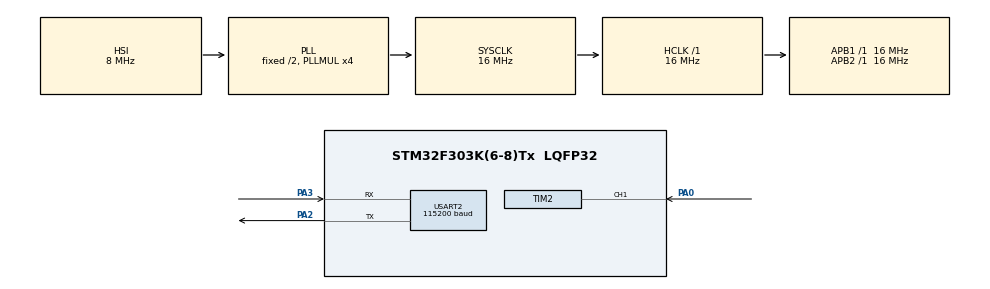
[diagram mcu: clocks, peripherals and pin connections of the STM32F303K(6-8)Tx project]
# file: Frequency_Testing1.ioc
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Mcu.Family=STM32F3
Mcu.Name=STM32F303K(6-8)Tx
Mcu.Package=LQFP32
NVIC.PriorityGroup=NVIC_PRIORITYGROUP_4
NVIC.TIM2_IRQn=true\:0\:0\:false\:false\:true\:true\:true\:true
NVIC.TIM7_DAC2_IRQn=true\:15\:0\:false\:false\:true\:false\:true\:true
NVIC.TimeBase=TIM7_DAC2_IRQn
NVIC.TimeBaseIP=TIM7
PA0.Signal=S_TIM2_CH1_ETR
PA13.Mode=Serial_Wire
PA13.Signal=SYS_JTMS-SWDIO
PA14.Mode=Serial_Wire
PA14.Signal=SYS_JTCK-SWCLK
PA2.Mode=Asynchronous
PA2.Signal=USART2_TX
PA3.Mode=Asynchronous
PA3.Signal=USART2_RX
PF0\ /\ OSC_IN.Mode=HSE-External-Clock-Source
PF0\ /\ OSC_IN.Signal=RCC_OSC_IN
ProjectManager.HeapSize=0x200
ProjectManager.StackSize=0x400
ProjectManager.TargetToolchain=STM32CubeIDE
RCC.AHBFreq_Value=16000000
RCC.APB1Freq_Value=16000000
RCC.APB1TimFreq_Value=16000000
RCC.APB2Freq_Value=16000000
RCC.APB2TimFreq_Value=16000000
RCC.CortexFreq_Value=16000000
RCC.HCLKFreq_Value=16000000
RCC.HSE_VALUE=8000000
RCC.HSI_VALUE=8000000
RCC.PLLMUL=RCC_PLL_MUL4
RCC.SYSCLKFreq_VALUE=16000000
RCC.SYSCLKSourceVirtual=RCC_SYSCLKSOURCE_PLLCLK
SH.S_TIM2_CH1_ETR.0=TIM2_CH1,Input_Capture1_from_TI1
TIM2.Channel-Input_Capture1_from_TI1=TIM_CHANNEL_1
TIM2.Prescaler=16-1
USART2.BaudRate=115200
USART2.VirtualMode-Asynchronous=VM_ASYNC
VP_SYS_VS_tim7.Mode=TIM7
VP_TIM2_VS_ClockSourceINT.Mode=Internal
board=custom

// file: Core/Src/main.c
/* USER CODE BEGIN Header */
/**
  ******************************************************************************
  * @file           : main.c
  * @brief          : Main program body
  ******************************************************************************
  * @attention
  *
  * Copyright (c) 2024 STMicroelectronics.
  * All rights reserved.
  *
  * This software is licensed under terms that can be found in the LICENSE file
  * in the root directory of this software component.
  * If no LICENSE file comes with this software, it is provided AS-IS.
  *
  ******************************************************************************
  */
/* USER CODE END Header */
#include "main.h"
#include "stdio.h"
#include "string.h"

TIM_HandleTypeDef htim2;

UART_HandleTypeDef huart2;

void SystemClock_Config(void);
static void MX_GPIO_Init(void);
static void MX_USART2_UART_Init(void);
static void MX_TIM2_Init(void);

/* USER CODE BEGIN 0 */
#define TIMCLOCK   16000000
#define PRESCALER  15

uint32_t IC_Val1 = 0;
uint32_t IC_Val2 = 0;
uint32_t Difference = 0;
int Is_First_Captured = 0;
float frequency = 0;

void Print_Frequency(void) {
    char buffer[50]; // Buffer to hold the string
    int len = sprintf(buffer, "Frequency: %.2f Hz\r\n", frequency); // Format  string
    HAL_UART_Transmit(&huart2, (uint8_t *)buffer, len, HAL_MAX_DELAY); // Send string over UART
}

float Calculate_Resistance(float frequency, float capacitance) {
    return ((1.44 / (frequency * capacitance) - 1000)) / 2;
}

float Calculate_Capacitance(float frequency, float resistance) {
    return (1.44 / frequency) / (12000);
}

void Print_Resistance(float resistance) {
    char buffer[50];
    int len = sprintf(buffer, "Resistance: %.2f Ohms\r\n", resistance);
    HAL_UART_Transmit(&huart2, (uint8_t *)buffer, len, HAL_MAX_DELAY);
}

void Print_Capacitance(float capacitance) {
    char buffer[50];
    int len = sprintf(buffer, "Capacitance: %.2f Farads\r\n", capacitance);
    HAL_UART_Transmit(&huart2, (uint8_t *)buffer, len, HAL_MAX_DELAY);
}

// Measure Frequency

void HAL_TIM_IC_CaptureCallback(TIM_HandleTypeDef *htim)
{
	if (htim->Channel == HAL_TIM_ACTIVE_CHANNEL_1)
	{
		// If the first rising edge is not captured
		if (Is_First_Captured==0)
		{
			IC_Val1 = HAL_TIM_ReadCapturedValue(htim, TIM_CHANNEL_1); // read the first value
			Is_First_Captured = 1;  // set the first captured as true
		}

		else   // If the first rising edge is captured, the second edge will be captured
		{
			// Read second value
			IC_Val2 = HAL_TIM_ReadCapturedValue(htim, TIM_CHANNEL_1);

			if (IC_Val2 > IC_Val1)
			{
				// Calculate time difference between clock edges
				Difference = IC_Val2-IC_Val1;
			}

			else if (IC_Val1 > IC_Val2)
			{
				// Calculate the time difference when timer has overflowed
				Difference = (0xffffffff - IC_Val1) + IC_Val2;
			}

			float refClock = TIMCLOCK/(PRESCALER);

			frequency = refClock/Difference;

			// Reset the counter
			__HAL_TIM_SET_COUNTER(htim, 0);

			// Set Is_First_Captured back to false
			Is_First_Captured = 0;

			Print_Frequency();

			// Value of known capacitor in circuit in Farads
			float capacitance = 1e-6;
			float resistance = Calculate_Resistance(frequency, capacitance);
			Print_Resistance(resistance);

			// Value of known resistor in circuit in Ohms
			float resistance_known = 1000;
			float capacitance_calculated = Calculate_Capacitance(frequency, resistance_known);
			Print_Capacitance(capacitance_calculated);
		}
	}
}
/* USER CODE END 0 */

int main(void)
{

  /* MCU Configuration--------------------------------------------------------*/

  /* Reset of all peripherals, Initializes the Flash interface and the Systick. */
  HAL_Init();

  /* Configure the system clock */
  SystemClock_Config();

  /* Initialize all configured peripherals */
  MX_GPIO_Init();
  MX_USART2_UART_Init();
  MX_TIM2_Init();
  /* USER CODE BEGIN 2 */
  TIM1->CCR1 = 50;
  HAL_TIM_IC_Start_IT(&htim2, TIM_CHANNEL_1);
  /* USER CODE END 2 */

  /* Infinite loop */
  while (1)
  {

  }
}

void SystemClock_Config(void)
{
  RCC_OscInitTypeDef RCC_OscInitStruct = {0};
  RCC_ClkInitTypeDef RCC_ClkInitStruct = {0};

  /** Initializes the RCC Oscillators according to the specified parameters
  * in the RCC_OscInitTypeDef structure.
  */
  RCC_OscInitStruct.OscillatorType = RCC_OSCILLATORTYPE_HSI;
  RCC_OscInitStruct.HSIState = RCC_HSI_ON;
  RCC_OscInitStruct.HSICalibrationValue = RCC_HSICALIBRATION_DEFAULT;
  RCC_OscInitStruct.PLL.PLLState = RCC_PLL_ON;
  RCC_OscInitStruct.PLL.PLLSource = RCC_PLLSOURCE_HSI;
  RCC_OscInitStruct.PLL.PLLMUL = RCC_PLL_MUL4;
  if (HAL_RCC_OscConfig(&RCC_OscInitStruct) != HAL_OK)
  {
    Error_Handler();
  }

  /** Initializes the CPU, AHB and APB buses clocks
  */
  RCC_ClkInitStruct.ClockType = RCC_CLOCKTYPE_HCLK|RCC_CLOCKTYPE_SYSCLK
                              |RCC_CLOCKTYPE_PCLK1|RCC_CLOCKTYPE_PCLK2;
  RCC_ClkInitStruct.SYSCLKSource = RCC_SYSCLKSOURCE_PLLCLK;
  RCC_ClkInitStruct.AHBCLKDivider = RCC_SYSCLK_DIV1;
  RCC_ClkInitStruct.APB1CLKDivider = RCC_HCLK_DIV1;
  RCC_ClkInitStruct.APB2CLKDivider = RCC_HCLK_DIV1;

  if (HAL_RCC_ClockConfig(&RCC_ClkInitStruct, FLASH_LATENCY_0) != HAL_OK)
  {
    Error_Handler();
  }
}

static void MX_TIM2_Init(void)
{

  TIM_ClockConfigTypeDef sClockSourceConfig = {0};
  TIM_MasterConfigTypeDef sMasterConfig = {0};
  TIM_IC_InitTypeDef sConfigIC = {0};

  htim2.Instance = TIM2;
  htim2.Init.Prescaler = 16-1;
  htim2.Init.CounterMode = TIM_COUNTERMODE_UP;
  htim2.Init.Period = 4294967295;
  htim2.Init.ClockDivision = TIM_CLOCKDIVISION_DIV1;
  htim2.Init.AutoReloadPreload = TIM_AUTORELOAD_PRELOAD_DISABLE;
  if (HAL_TIM_Base_Init(&htim2) != HAL_OK)
  {
    Error_Handler();
  }
  sClockSourceConfig.ClockSource = TIM_CLOCKSOURCE_INTERNAL;
  if (HAL_TIM_ConfigClockSource(&htim2, &sClockSourceConfig) != HAL_OK)
  {
    Error_Handler();
  }
  if (HAL_TIM_IC_Init(&htim2) != HAL_OK)
  {
    Error_Handler();
  }
  sMasterConfig.MasterOutputTrigger = TIM_TRGO_RESET;
  sMasterConfig.MasterSlaveMode = TIM_MASTERSLAVEMODE_DISABLE;
  if (HAL_TIMEx_MasterConfigSynchronization(&htim2, &sMasterConfig) != HAL_OK)
  {
    Error_Handler();
  }
  sConfigIC.ICPolarity = TIM_INPUTCHANNELPOLARITY_RISING;
  sConfigIC.ICSelection = TIM_ICSELECTION_DIRECTTI;
  sConfigIC.ICPrescaler = TIM_ICPSC_DIV1;
  sConfigIC.ICFilter = 0;
  if (HAL_TIM_IC_ConfigChannel(&htim2, &sConfigIC, TIM_CHANNEL_1) != HAL_OK)
  {
    Error_Handler();
  }

}

static void MX_USART2_UART_Init(void)
{

  huart2.Instance = USART2;
  huart2.Init.BaudRate = 115200;
  huart2.Init.WordLength = UART_WORDLENGTH_8B;
  huart2.Init.StopBits = UART_STOPBITS_1;
  huart2.Init.Parity = UART_PARITY_NONE;
  huart2.Init.Mode = UART_MODE_TX_RX;
  huart2.Init.HwFlowCtl = UART_HWCONTROL_NONE;
  huart2.Init.OverSampling = UART_OVERSAMPLING_16;
  huart2.Init.OneBitSampling = UART_ONE_BIT_SAMPLE_DISABLE;
  huart2.AdvancedInit.AdvFeatureInit = UART_ADVFEATURE_NO_INIT;
  if (HAL_UART_Init(&huart2) != HAL_OK)
  {
    Error_Handler();
  }

}

static void MX_GPIO_Init(void)
{

  /* GPIO Ports Clock Enable */
  __HAL_RCC_GPIOF_CLK_ENABLE();
  __HAL_RCC_GPIOA_CLK_ENABLE();

}

void HAL_TIM_PeriodElapsedCallback(TIM_HandleTypeDef *htim)
{
  if (htim->Instance == TIM7) {
    HAL_IncTick();
  }
}

void Error_Handler(void)
{
  __disable_irq();
  while (1)
  {
  }
}
